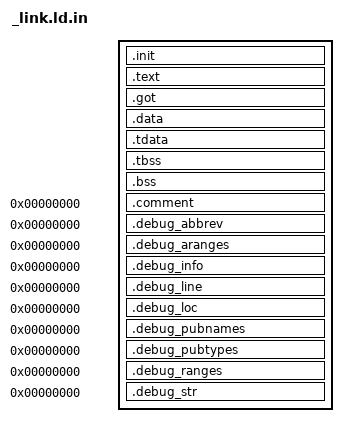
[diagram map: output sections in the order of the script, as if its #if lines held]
STARTUP(LIBC_PATH/arch/UARCH/src/entry.o)
ENTRY(__entry)

PHDRS {
	text PT_LOAD FILEHDR PHDRS FLAGS(5);
	data PT_LOAD FLAGS(6);
	tls PT_TLS;
	debug PT_NOTE;
}

SECTIONS {
	. = SEGMENT_START("text-segment", 0x400000);
#ifndef SHLIB
	PROVIDE (__executable_start = .);
#endif
	. = . + SIZEOF_HEADERS;

	.init : {
		*(.init);
	} :text

	.text : {
		*(.text .text.*);
		*(.rodata .rodata.*);
	} :text

	. = . + 0x4000;

	.got : {
		 *(.got*);
	} :data

	.data : {
		*(.data);
		*(.sdata);
	} :data

	.tdata : {
		*(.tdata);
		*(.tdata.*);
		*(.gnu.linkonce.td.*);
	} :data :tls

	.tbss : {
		*(.tbss);
		*(.tbss.*);
		*(.gnu.linkonce.tb.*);
	} :data :tls

	.bss : {
		*(.sbss);
		*(COMMON);
		*(.bss);
	} :data

	_end = .;

#ifdef CONFIG_LINE_DEBUG
	.comment 0 : { *(.comment); } :debug
	.debug_abbrev 0 : { *(.debug_abbrev); } :debug
	.debug_aranges 0 : { *(.debug_aranges); } :debug
	.debug_info 0 : { *(.debug_info); } :debug
	.debug_line 0 : { *(.debug_line); } :debug
	.debug_loc 0 : { *(.debug_loc); } :debug
	.debug_pubnames 0 : { *(.debug_pubnames); } :debug
	.debug_pubtypes 0 : { *(.debug_pubtypes); } :debug
	.debug_ranges 0 : { *(.debug_ranges); } :debug
	.debug_str 0 : { *(.debug_str); } :debug
#endif

	/DISCARD/ : {
		*(*);
	}
}
